# BlockA: IP-XACT component
VLNV example.org:FutureLib:BlockA:1.0

## Address spaces and blocks
BlockAMap.BlockARegs: base 0x0000, range 0x100, width 32

## Registers
Registers are 32-bit, read-write, no defined reset value unless marked. A register's access mark holds for its fields unless they carry their own. Offsets are from the block's base; lines under a group give offsets from that group; [hi:lo] are bit positions; {n}, {i} and the like mark numbered series; 'fields as' and 'values as' point back to an identical list; <NAME> marks a mode.

## BlockAMap.BlockARegs
Base 0x00000000
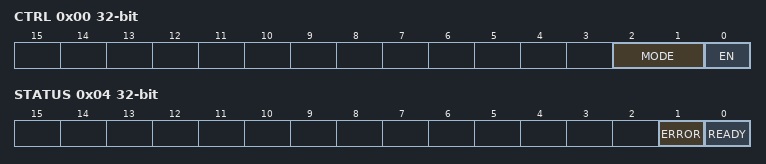
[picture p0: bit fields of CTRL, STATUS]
0x00 CTRL
  [2:1] MODE, [0] EN
0x04 STATUS ro
  [1] ERROR, [0] READY
0x08 DATA wo
  [31:0] VALUE
0x0C INT_EN
  [0] IE
0x10 INT_STATUS ro
  [0] IRQ
